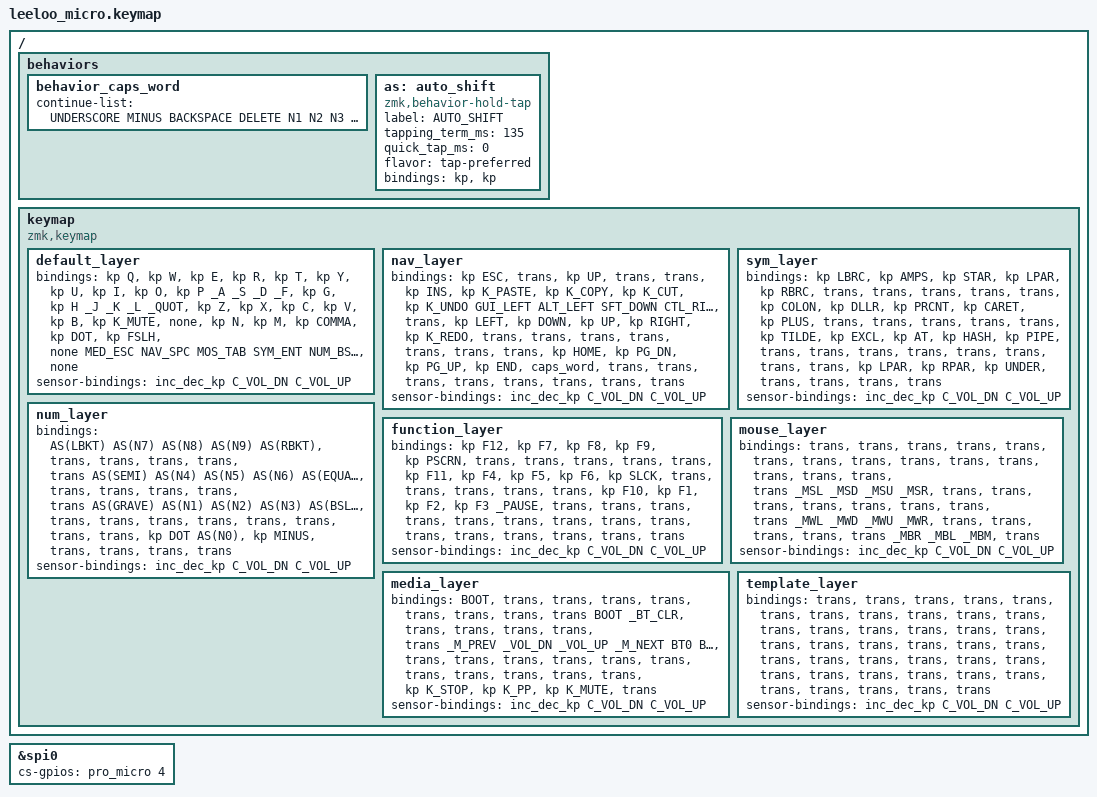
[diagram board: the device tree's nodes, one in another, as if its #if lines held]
/*
 * Copyright (c) 2023 The ZMK Contributors
 * SPDX-License-Identifier: MIT
 */

#include <behaviors.dtsi>
#include <dt-bindings/zmk/outputs.h>
#include <dt-bindings/zmk/keys.h>
#include <dt-bindings/zmk/bt.h>
#include <dt-bindings/zmk/rgb.h>

#include <dt-bindings/zmk/mouse.h>

/*
 * Assign the cs-gpios pin to 4.
 * Uncomment these next few lines if implementing nice!view Displays.
 */
nice_view_spi: &spi0 {
  cs-gpios = <&pro_micro 4 GPIO_ACTIVE_HIGH>;
};

// Short bluetooth.
#define BT0         &bt BT_SEL 0
#define BT1         &bt BT_SEL 1
#define BT2         &bt BT_SEL 2
#define BT3         &bt BT_SEL 3
#define BT4         &bt BT_SEL 4
#define _BT_CLR     &bt BT_CLR

#define BOOT        &bootloader

// Home row mods - Left
#define _A &hmr_left LGUI A
#define _S &hmr_left LALT S
#define _D &hmr_left LSFT D
#define _F &hmr_left LCTL F

// Home row mods - Right
#define _J    &hmr_right LCTL J
#define _K    &hmr_right LSFT K
#define _L    &hmr_right LALT L
#define _SEMI &hmr_right LGUI SEMI
#define _QUOT &hmr_right LGUI QUOT

// Left thumbs
#define NAV_BS  &lt 1 BSPC
#define MOS_TAB &lt 5 TAB
#define MED_ESC &lt 6 ESC

// Right thumbs
#define NUM_SPC &lt 2 SPACE
#define SYM_ENT &lt 3 ENTER
#define FUN_DEL &lt 4 DEL

// Just some short versions
#define _PAUSE &kp PAUSE_BREAK

// Mouse movement.
#define _MSU &mmv MOVE_UP
#define _MSD &mmv MOVE_DOWN
#define _MSL &mmv MOVE_LEFT
#define _MSR &mmv MOVE_RIGHT

// Mouse wheel movement.
#define _MWU &mwh SCROLL_UP
#define _MWD &mwh SCROLL_DOWN
#define _MWL &mwh SCROLL_LEFT
#define _MWR &mwh SCROLL_RIGHT

// Mouse buttons
#define _MBL &mkp MB1
#define _MBR &mkp MB2
#define _MBM &mkp MB3

#define LEFT_KEYS				\
  0 1 2 3 4					\
  10 11 12 13 14				\
  20 21 22 23 24
#define RIGHT_KEYS				\
  5 6 7 8 9					\
  15 16 17 18 19				\
  27 28 29 30 31
#define THUMB_KEYS   \
  32 33 34 35        \
  36 37 38 29

/ {

  behaviors {

    #include "common-behaviors.h"

    //
    // CapsWord - ported from Pascal Getreuer's extension for QMK
    // - https://zmk.dev/docs/behaviors/caps-word
    // - https://getreuer.info/posts/keyboards/caps-word/index.html
    //
    behavior_caps_word {
        continue-list = <UNDERSCORE MINUS BACKSPACE DELETE N1 N2 N3 N4 N5 N6 N7 N8 N9 N0>;
    };

    // Autoshift.
    as: auto_shift {
      compatible = "zmk,behavior-hold-tap";
      label = "AUTO_SHIFT";
      #binding-cells = <2>;
      tapping_term_ms = <135>;
      quick_tap_ms = <0>;
      flavor = "tap-preferred";
      bindings = <&kp>, <&kp>;
    };
    #define AS(keycode) &as LS(keycode) keycode

  };

  keymap {
    compatible = "zmk,keymap";

    // A very Miryoku like default layer. Changes include:
    // - QWERTY
    // - Kinesis Advantage like space, enter and backspace
    default_layer {
      bindings = <
        &kp Q      &kp W      &kp E      &kp R      &kp T                 /**/               &kp Y      &kp U      &kp I      &kp O      &kp P
        _A         _S         _D         _F         &kp G                 /**/               &kp H      _J         _K         _L         _QUOT
        &kp Z      &kp X      &kp C      &kp V      &kp B     &kp K_MUTE  /**/  &none        &kp N      &kp M      &kp COMMA  &kp DOT    &kp FSLH
#ifdef TRUE_MIRYOKU
                              &none      MED_ESC    NAV_SPC   MOS_TAB     /**/  SYM_ENT      NUM_BS     FUN_DEL    &none
#else
                              &none      MED_ESC    NAV_BS    MOS_TAB     /**/  SYM_ENT      NUM_SPC    FUN_DEL    &none
#endif
        >;

      sensor-bindings = <&inc_dec_kp C_VOL_DN C_VOL_UP>;
    };

    // Layer 1
    // Nav Layer
    // Miryoku like:
    // - vi style nav
    // - insert moved off pinky (which is there due to the vi style
    //   nav), shuffling the other keys like paste, copy, etc.
    // - ESC, location from Seniply. This might be more ergonomic than
    //   the tucky thum ESC on the base layer
    // - some nav keys added to the left side to allow for some left
    //   handed nav
    #define GUI_LEFT &mt LGUI LEFT
    #define ALT_LEFT &mt LALT LEFT
    #define SFT_DOWN &mt LSFT DOWN
    #define CTL_RIGHT &mt LCTL RIGHT
    nav_layer {
      bindings = <
        &kp ESC    &trans     &kp UP     &trans     &trans             /**/              &kp INS    &kp K_PASTE &kp K_COPY  &kp K_CUT  &kp K_UNDO
        GUI_LEFT   ALT_LEFT   SFT_DOWN   CTL_RIGHT  &trans             /**/              &kp LEFT   &kp DOWN    &kp UP      &kp RIGHT  &kp K_REDO
        &trans     &trans     &trans     &trans     &trans     &trans  /**/   &trans     &kp HOME   &kp PG_DN   &kp PG_UP   &kp END    &caps_word
                              &trans     &trans     &trans     &trans  /**/   &trans     &trans     &trans      &trans
        >;

      sensor-bindings = <&inc_dec_kp C_VOL_DN C_VOL_UP>;
    };

    // Layer 2
    // - Num layer
    // - Miryoku
    num_layer {
      bindings = <
        AS(LBKT)   AS(N7)     AS(N8)     AS(N9)     AS(RBKT)            /**/              &trans     &trans     &trans     &trans     &trans
        AS(SEMI)   AS(N4)     AS(N5)     AS(N6)     AS(EQUAL)           /**/              &trans     &trans     &trans     &trans     &trans
        AS(GRAVE)  AS(N1)     AS(N2)     AS(N3)     AS(BSLH)  &trans    /**/   &trans     &trans     &trans     &trans     &trans     &trans
                              &trans     &kp DOT    AS(N0)    &kp MINUS /**/   &trans     &trans     &trans     &trans
        >;

      sensor-bindings = <&inc_dec_kp C_VOL_DN C_VOL_UP>;
    };

    // Layer 3
    // - Sym layer
    // - Miryoku
    sym_layer {
      bindings = <
        &kp LBRC   &kp AMPS   &kp STAR   &kp LPAR   &kp RBRC             /**/              &trans     &trans     &trans     &trans     &trans
        &kp COLON  &kp DLLR   &kp PRCNT  &kp CARET  &kp PLUS             /**/              &trans     &trans     &trans     &trans     &trans
        &kp TILDE  &kp EXCL   &kp AT     &kp HASH   &kp PIPE   &trans    /**/   &trans     &trans     &trans     &trans     &trans     &trans
                              &trans     &kp LPAR   &kp RPAR   &kp UNDER /**/   &trans     &trans     &trans     &trans
        >;

      sensor-bindings = <&inc_dec_kp C_VOL_DN C_VOL_UP>;
    };

    // Layer 4
    // - Function layer
    // - Miryoku
    function_layer {
      bindings = <
        &kp F12    &kp F7     &kp F8     &kp F9     &kp PSCRN          /**/              &trans     &trans     &trans     &trans     &trans
        &kp F11    &kp F4     &kp F5     &kp F6     &kp SLCK           /**/              &trans     &trans     &trans     &trans     &trans
        &kp F10    &kp F1     &kp F2     &kp F3     _PAUSE     &trans  /**/   &trans     &trans     &trans     &trans     &trans     &trans
                              &trans     &trans     &trans     &trans  /**/   &trans     &trans     &trans     &trans
        >;

      sensor-bindings = <&inc_dec_kp C_VOL_DN C_VOL_UP>;
    };

    // Layer 5
    // - Mouse layer
    // - Miryoku like, but vi shifted style navigation
#if 1
    mouse_layer {
      bindings = <
        &trans     &trans     &trans     &trans     &trans             /**/              &trans     &trans     &trans     &trans     &trans
        &trans     &trans     &trans     &trans     &trans             /**/              _MSL       _MSD       _MSU       _MSR       &trans
        &trans     &trans     &trans     &trans     &trans     &trans  /**/   &trans     _MWL       _MWD       _MWU       _MWR       &trans
                              &trans     &trans     &trans     &trans  /**/   _MBR       _MBL       _MBM       &trans
        >;

      sensor-bindings = <&inc_dec_kp C_VOL_DN C_VOL_UP>;
    };
#else
    dummy_mouse_layer {
      bindings = <
        &trans     &trans     &trans     &trans     &trans             /**/              &trans     &trans     &trans     &trans     &trans
        &trans     &trans     &trans     &trans     &trans             /**/              &trans     &trans     &trans     &trans     &trans
        &trans     &trans     &trans     &trans     &trans     &trans  /**/   &trans     &trans     &trans     &trans     &trans     &trans
                              &trans     &trans     &trans     &trans  /**/   &trans     &trans     &trans     &trans
        >;

      sensor-bindings = <&inc_dec_kp C_VOL_DN C_VOL_UP>;
    };
#endif

    #define _VOL_UP &kp  C_VOL_UP
    #define _VOL_DN &kp  C_VOL_DN
    #define _M_NEXT &kp  C_NEXT
    #define _M_PREV &kp  C_PREV

    // Layer 6
    // - Media layer
    // - Miryoku, no power toggle or rgb though.
    // - Bluetooth profiles on the left side as that makes more sense
    //   to me with the left being the master.
    media_layer {
      bindings = <
        BOOT       &trans     &trans     &trans     &trans             /**/              &trans     &trans     &trans     &trans     BOOT
        _BT_CLR    &trans     &trans     &trans     &trans             /**/              &trans     _M_PREV    _VOL_DN    _VOL_UP    _M_NEXT
        BT0        BT1        BT2        BT3        BT4        &trans  /**/   &trans     &trans     &trans     &trans     &trans     &trans
                              &trans     &trans     &trans     &trans  /**/   &kp K_STOP &kp K_PP   &kp K_MUTE &trans
        >;

      sensor-bindings = <&inc_dec_kp C_VOL_DN C_VOL_UP>;
    };

    template_layer {
      bindings = <
        &trans     &trans     &trans     &trans     &trans             /**/              &trans     &trans     &trans     &trans     &trans
        &trans     &trans     &trans     &trans     &trans             /**/              &trans     &trans     &trans     &trans     &trans
        &trans     &trans     &trans     &trans     &trans     &trans  /**/   &trans     &trans     &trans     &trans     &trans     &trans
                              &trans     &trans     &trans     &trans  /**/   &trans     &trans     &trans     &trans
        >;

      sensor-bindings = <&inc_dec_kp C_VOL_DN C_VOL_UP>;
    };
  };
};

// Local Variables:
// mode: c
// c-basic-offset: 2
// eval: (c-set-offset 'cpp-macro 0 nil)
// eval: (c-set-offset 'label 2 nil)
// End:
